# nrf7120E_enga_wificore register map
Vendor: Nordic Semiconductor; Series: nrf71; File version: 1
Registers are 32-bit, read-write, reset 0x0 unless marked. A register's access mark holds for its fields unless they carry their own. Offsets are from the block's base; [hi:lo] are bit positions; lines under a group give offsets from that group; {n}, {i} and the like mark numbered series; 'fields as' and 'values as' point back to an identical list.

## GLOBAL_WICR — Wi-Fi Information Configuration Registers
Base 0x003FD000
0x00 FIRMWARE group — Unspecified
  0x00 LMACINITPC reset 0x28080000 — Boot address for LMAC processor (defaults to start of Wi-Fi core ROM_0)
    [31:0] INITPC — LMAC boot vector
  0x04 UMACINITPC reset 0x28180000 — Boot address for UMAC processor (defaults to start of Wi-Fi core ROM_1)
    [31:0] INITPC — UMAC boot vector
  0x08 LMACROMPATCHADDR — Address in MRAM for LMAC ROM patch
    [31:0] Address — LMAC ROM patch address
  0x0C UMACROMPATCHADDR — Address in MRAM for UMAC ROM patch
    [31:0] Address — UMAC ROM patch address
0x80 IPCCONFIG group — Unspecified
  0x00 COMMANDMBOXADDR — Base address of command mailbox
    [31:0] ADDRESS — Base address of mailbox
  0x04 COMMANDMBOXSIZE — Size of command mailbox in bytes
    [31:0] SIZE — Size in bytes
  0x08 EVENTMBOXADDR — Base address of event mailbox
    [31:0] ADDRESS — Base address of mailbox
  0x0C EVENTMBOXSIZE — Size of event mailbox in bytes
    [31:0] SIZE — Size in bytes
  0x10 SPAREMBOXADDR — Base address of spare mailbox
    [31:0] ADDRESS — Base address of mailbox
  0x14 SPAREMBOXSIZE — Size of spare mailbox in bytes
    [31:0] SIZE — Size in bytes
0x100 VTFDATA reset 0xFFFFFFFF — Pointer to memory location containing VTF data from the VTF monitoring system
  [31:0] ADDRESS — Address of the VTF monitoring data in RAM
0x104 RFPARAMSDATAADDR — Base address of RF parameter data
  [31:0] ADDRESS
0x108 RFPARAMSDATASIZE — Size of RF parameter data in bytes
  [31:0] SIZE — Size in bytes

## LRCCONF_LRC0 — LRCCONF
Base 0x4800B000
{0x0+4i} TASKS_REQCLKSRC[{i}] (i=0..7) wo — Description collection: Request the clock source for clock [n]
  [0] TASKS_REQCLKSRC — Request the clock source for clock [n]
    1=Trigger task
{0x20+4i} TASKS_STOPREQCLKSRC[{i}] (i=0..7) wo — Description collection: Stop requesting the clock source for clock [n]
  [0] TASKS_STOPREQCLKSRC — Stop requesting the clock source for clock [n]
    1=Trigger task
0x40 TASKS_CONSTLAT group — Peripheral tasks.
  0x00 ENABLE wo — Enable constant latency mode
    [0] ENABLE
      1=Trigger task
  0x04 DISABLE wo — Disable constant latency mode
    [0] DISABLE
      1=Trigger task
0x48 TASKS_SYSTEMOFF group — Peripheral tasks.
  0x00 NOTREADY wo — Not ready to go to System OFF
    [0] NOTREADY
      1=Trigger task
  0x04 READY wo — Ready to go to System OFF
    [0] READY
      1=Trigger task
0x50 TASKS_REQHFXO wo — Request HFXO
  [0] TASKS_REQHFXO
    1=Trigger task
0x54 TASKS_STOPREQHFXO wo — Stop requesting HFXO
  [0] TASKS_STOPREQHFXO
    1=Trigger task
{0x100+4i} EVENTS_CLKSRCSTARTED[{i}] (i=0..7) — Description collection: Clock source is started for clock [n]
  [0] EVENTS_CLKSRCSTARTED — Clock source is started for clock [n]
    0=NotGenerated (Event not generated); 1=Generated (Event generated)
0x120 EVENTS_HFXOSTARTED — HFXO is started
  [0] EVENTS_HFXOSTARTED
    values as EVENTS_CLKSRCSTARTED[0].EVENTS_CLKSRCSTARTED
{0x400+8i} CLKSTAT[{i}] (i=0..7) group — Unspecified
  0x00 RUN — Description cluster: Status indicating that TASKS_REQCLKSRC task has been triggered for clock [n].
    [0] STATUS ro — Clock start task triggered or not
      0=NotTriggered (Task not triggered); 1=Triggered (Task triggered)
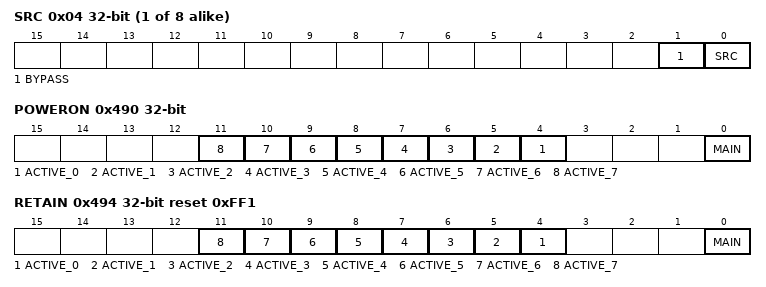
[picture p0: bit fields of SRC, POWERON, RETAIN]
  0x04 SRC — Description cluster: Status indicating clock source for clock [n]
    [1] BYPASS ro — Clock source bypass status
      0=Disable (Clock source bypass is disabled.); 1=Enable (Clock source bypass is enabled.)
    [0] SRC ro — Clock source status
      0=OpenLoop; 1=ClosedLoop
{0x440+8i} CLKCTRL[{i}] (i=0..7) group — Unspecified
  0x00 ALWAYSRUN — Description cluster: Force the clock [n] and tree running always
    [0] FORCE — Force the clock always running
      0=Automatic clock control enabled; 1=AlwaysRun (Clock always running)
  0x04 SRC — Description cluster: Select the clock source for clock [n]
    [1] BYPASS — Clock source bypass
      0=Disable the clock source bypass; 1=Enable the clock source bypass
    [0] SRC — Clock source
      0=OpenLoop; 1=ClosedLoop
0x480 CONSTLATSTAT ro — Status of constant latency
  [0] STATUS
    0=Disable (Constant latency disabled.); 1=Enable (Constant latency enabled.)
0x490 POWERON — Force power domain ON
  [all] fields
    0=Automatic power control enabled; 1=AlwaysOn (Keep the power domain ON even though there is no request)
  [n+4] ACTIVE_{n} (n=0..7) — Force the active power domain[{n}] ON
  [0] MAIN — Force the main power domain ON
0x494 RETAIN reset 0xFF1 — Retain power domain
  [all] fields
    0=Disable (Retain disabled); 1=Enable (Retain enabled)
  [n+4] ACTIVE_{n} (n=0..7) — Retain the active power domain[{n}]
  [0] MAIN ro — Retain the main power domain
{0x500+4i} AX2XWAITSTATES[{i}] (i=0..15) — Description collection: AX2X bridge waitstates for the domain [n], where n is the Domain ID.
  [2:0] WAITSTATES — Number of waitstates

## Notices in the file
Copyright (c) 2010 - 2026, Nordic Semiconductor ASA All rights reserved.
SPDX-License-Identifier: BSD-3-Clause
Redistribution and use in source and binary forms, with or without
modification, are permitted provided that the following conditions are met:
1. Redistributions of source code must retain the above copyright notice, this
list of conditions and the following disclaimer.
2. Redistributions in binary form must reproduce the above copyright
notice, this list of conditions and the following disclaimer in the
documentation and/or other materials provided with the distribution.
3. Neither the name of Nordic Semiconductor ASA nor the names of its
contributors may be used to endorse or promote products derived from this
software without specific prior written permission.
THIS SOFTWARE IS PROVIDED BY THE COPYRIGHT HOLDERS AND CONTRIBUTORS "AS IS"
AND ANY EXPRESS OR IMPLIED WARRANTIES, INCLUDING, BUT NOT LIMITED TO, THE
IMPLIED WARRANTIES OF MERCHANTABILITY, AND FITNESS FOR A PARTICULAR PURPOSE
ARE DISCLAIMED. IN NO EVENT SHALL NORDIC SEMICONDUCTOR ASA OR CONTRIBUTORS BE
LIABLE FOR ANY DIRECT, INDIRECT, INCIDENTAL, SPECIAL, EXEMPLARY, OR
CONSEQUENTIAL DAMAGES (INCLUDING, BUT NOT LIMITED TO, PROCUREMENT OF
SUBSTITUTE GOODS OR SERVICES; LOSS OF USE, DATA, OR PROFITS; OR BUSINESS
INTERRUPTION) HOWEVER CAUSED AND ON ANY THEORY OF LIABILITY, WHETHER IN
CONTRACT, STRICT LIABILITY, OR TORT (INCLUDING NEGLIGENCE OR OTHERWISE)
ARISING IN ANY WAY OUT OF THE USE OF THIS SOFTWARE, EVEN IF ADVISED OF THE
POSSIBILITY OF SUCH DAMAGE.
